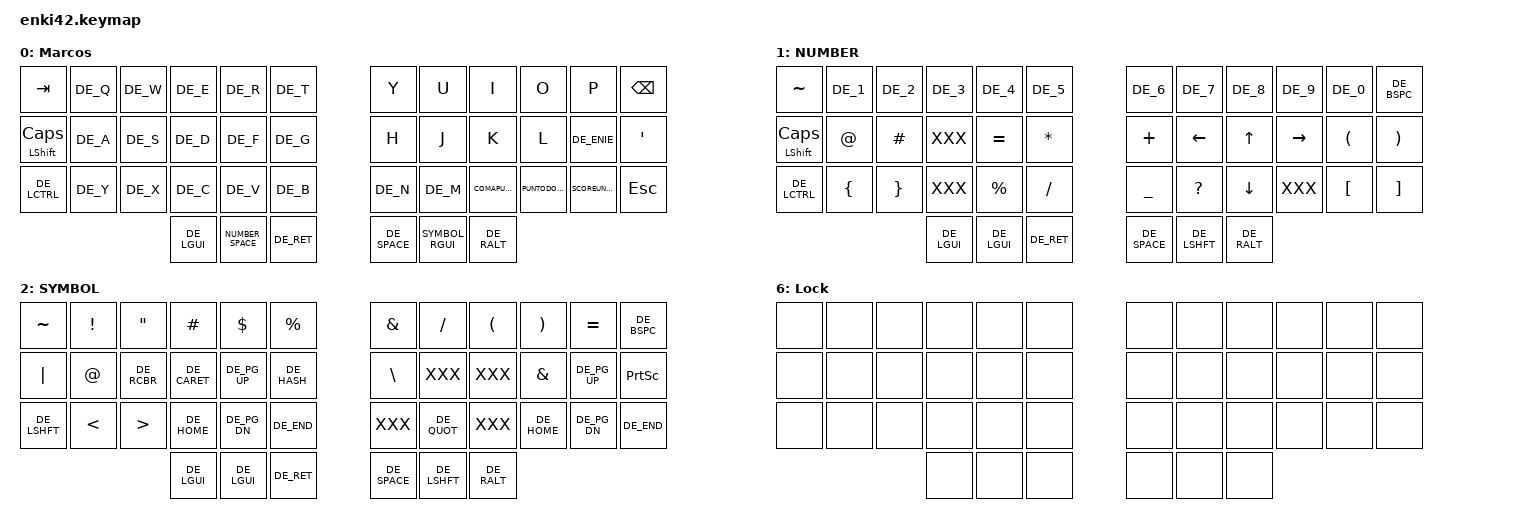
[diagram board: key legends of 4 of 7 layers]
/* ========================================
FileName: corne.keymap
Date: 15:17 23.September.2022
Author: Marcos Chow Castro
Email: mctechnology170318@gmail.com
GitHub: https://github.com/mctechnology17
Brief: keymap for the wireless corne keyboard
                             ╔═╦═╦═╗
                      ╔════╗ ║║║║║╔╝
                      ║╔╗╔╗║ ║║║║║╚╗
                      ╚╝║║╚╝ ║╠═╩╩═╝
                        ║╠═╦═╣╚╦═╦╦═╦╗╔═╦═╦╦╗
                        ║║╩╣═╣║║║║║╬║╚╣╬║╬║║║
                        ╚╩═╩═╩╩╩╩═╩═╩═╩═╬╗╠╗║
                                        ╚═╩═╝
Copyright (c) 2020 The ZMK Contributors
SPDX-License-Identifier: MIT
========================================= */
// ### include {{{
#include <behaviors.dtsi>
#include <dt-bindings/zmk/keys.h>
#include <dt-bindings/zmk/bt.h>
#include <dt-bindings/zmk/outputs.h>
#include <dt-bindings/zmk/ext_power.h>
#include <dt-bindings/led/led.h>
#include <dt-bindings/zmk/backlight.h>
#include <dt-bindings/zmk/rgb.h>
#include <dt-bindings/zmk/reset.h>
#include "keymap_german_mac_iso_zmk.h"
#include "keypos_42keys.h"
#include "config_zmk.h"
//#include "mouse.dtsi"
//&led_strip {
//    chain-length = <27>;
//};
// }}}
/ {
// ### macros {{{
   macros {
      #include "macros.dtsi"
   };
// }}}
// ### combos {{{
   combos {
      compatible = "zmk,combos";

      unlock {
         bindings = <&to DEFAULT>;
         key-positions = <LT5 LH0 RH0 RT5>;
         layers = <LOCK>;
      };

      lock {
         bindings = <&to LOCK>;
         key-positions = <LT5 RH0>;
         layers = <LX_>;
      };
   };
// }}}
   // ### conditional_layers {{{
   conditional_layers {
        compatible = "zmk,conditional-layers";

        tri_layer {
            if-layers = <SYMBOL FUNCTION>;
            then-layer = <LX_>;
        };
    };

   //}}}

 // ### MOD MORPH {{{

 behaviors {
        COMAPUNTOCOMA: coma_puntocoma {
            compatible = "zmk,behavior-mod-morph";
            #binding-cells = <0>;
            bindings = <&kp COMMA>, <&kp SEMICOLON>;
            mods = <(MOD_LSFT)>;
        };
    };
 behaviors {
        PUNTODOSPUNTOS: punto_dospuntos {
            compatible = "zmk,behavior-mod-morph";
            #binding-cells = <0>;
            bindings = <&kp DOT>, <&kp COLON>;
            mods = <(MOD_LSFT)>;
        };
    };

 behaviors {
        SCOREUNDERSCORE: guion_guionbajo {
            compatible = "zmk,behavior-mod-morph";
            #binding-cells = <0>;
            bindings = <&kp MINUS>, <&kp UNDER>;
            mods = <(MOD_LSFT)>;
        };
    };


  //}}}
   keymap {
      compatible = "zmk,keymap";
      // ### default_layer {{{
      default_layer {
      /*.------------------------------------------------.                         .-------------------------------------------------.
         |TAB     |   Q   |   W   |   E   |   R   |   T   |                         |   Y   |   U   |   I   |   O   |   P   | BACKSPC |
         |--------+-------+-------+-------+-------+-------|                         |-------+-------+-------+-------+-------+---------|
         |SHIFT   |   A   |   S   |   D   |   F   |   G   |                         |   H   |   J   |   K   |   L   |  ñ    |   '     |
         |--------+-------+-------+-------+-------+-------|                         |-------+-------+-------+-------+-------+---------|
         |CTRL    |   Y   |   X   |   C   |   V   |   B   |                         |   N   |   M   |   ,   |  .    |  _    |   ESC   |
         '---------------------------------------------------------|       |----------------------------------------------------------'
                                  |  WIN    |  LT1       |   ENTER |       | SPACE | LT2 CMD   |  RALT |
                                  '--------------------------------'       '----------------------------------'*/
         display-name = "Marcos";
         bindings = <
         &kp TAB          DE_Q  DE_W  DE_E  DE_R  DE_T                      &kp Y   &kp U  &kp I           &kp O           &kp P      &kp BSPC
         &mt LSHIFT CLCK   DE_A   DE_S   DE_D   DE_F   DE_G                        &kp H   &kp J  &kp K           &kp L           DE_ENIE    &kp APOS   
         DE_LCTRL         DE_Y  DE_X  DE_C  DE_V  DE_B                      DE_N    DE_M   &COMAPUNTOCOMA  &PUNTODOSPUNTOS &SCOREUNDERSCORE  &kp ESC
                                  DE_LGUI  NUMBER_SPACE DE_RET           DE_SPACE SYMBOL_RGUI DE_RALT
            >;
      };
      // }}}
      // ### number_layer {{{
      number_layer {
       /*.-------------------------------------------------.                         .-------------------------------------------------.
         |    ~    |   1   |   2   |   3   |   4   |   5   |                         |   6   |   7   |   8   |   9   |   0   |BACKSPC  |
         |---------+-------+-------+-------+-------+-------|                         |-------+-------+-------+-------+-------+---------|
         | SHIFT   |   @   |   #   |       |   =   |   *   |                         |   +   |  LEFT |   UP  |  RIGHT|  (     |   )    |
         |---------+-------+-------+-------+-------+-------|                         |-------+-------+-------+-------+-------+---------|
         | CTRL   |    {  |   }    |       |   %   |   /   |                        |   -   |   ?   |  DOWN |       |  [     |   ]    |
         '----------------------------------------------------------|       |----------------------------------------------------------'
                                   |  WIN |  CMD  |     ENTER       |       |    SPACE    |  LSFT |      ALTGR    |
                                   '--------------------------------'       '--------------------------------'*/
         display-name = "NUMBER";
         bindings = <
         &kp TILDE       DE_1     DE_2       DE_3        DE_4        DE_5                        DE_6       DE_7          DE_8      DE_9        DE_0        DE_BSPC
         &mt LSHIFT CLCK &kp AT   &kp HASH   XXX           &kp EQUAL   &kp ASTRK                 &kp PLUS   &kp LEFT      &kp UP    &kp RIGHT   &kp LPAR    &kp RPAR
         DE_LCTRL        &kp LBRC &kp RBRC   XXX            &kp PERCENT &kp SLASH                &kp UNDER  &kp QUESTION  &kp DOWN    XXX       &kp LBKT    &kp RBKT
                                          DE_LGUI   DE_LGUI    DE_RET                               DE_SPACE DE_LSHFT DE_RALT
            >;
      };
      // }}}
      // ### symbol_layer {{{
      symbol_layer {
       /*.------------------------------------------------.          TODO:          .-------------------------------------------------.
         |    ~   |   !   |   "   |   #   |   $   |    %   |                         |  &    |   /   |   (   |   )   |   =   |BACKSPC  |
         |--------+-------+-------+-------+-------+-------|                         |-------+-------+-------+-------+-------+---------|
         |    |  |   @   |   }   |   ^   |       |   #    |                         |   \   |       |       |  &    |PAGE_UP|PRINTSCR |
         |--------+-------+-------+-------+-------+-------|                         |-------+-------+-------+-------+-------+---------|
         |SHIFT   |    <  |   >   |  HOME |PAGE_DO|  END  |                         |      |   '   |       |  HOME |PAGE_DO|   END   |
         '---------------------------------------------------------|       |----------------------------------------------------------'
                                  |  WIN    |  CMD        | ENTER  |       |  SPACE | LSFT |       ALTGR      |
                                  '--------------------------------'       '--------------------------------'*/
         display-name = "SYMBOL";
         bindings = <
         &kp TILDE &kp EXCL       &kp DQT          &kp HASH &kp DLLR   &kp PRCNT                  &kp AMPS       &kp SLASH   &kp LPAR  &kp RPAR &kp EQUAL DE_BSPC
         &kp PIPE  &kp AT         DE_RCBR          DE_CARET DE_PG_UP   DE_HASH                    &kp BACKSLASH    XXX        XXX      &kp AMPS DE_PG_UP  &kp PRINTSCREEN
         DE_LSHFT  &kp LESS_THAN  &kp GREATER_THAN DE_HOME  DE_PG_DN   DE_END                        XXX          DE_QUOT      XXX      DE_HOME  DE_PG_DN  DE_END
                                                    DE_LGUI   DE_LGUI    DE_RET                    DE_SPACE DE_LSHFT DE_RALT
         >;
      };
      // }}}
      // ### function_layer {{{
      function_layer {
       /*.------------------------------------------------.                         .-------------------------------------------------.
         |    F1  |  F2   |   F3  |   F4  | SPELL |TRADUCT|                         |DE_F13 | DE_F14|DE_F15 | DE_F16| BRI_DN| BRI_UP  |
         |--------+-------+-------+-------+-------+-------|                         |-------+-------+-------+-------+-------+---------|
         |    F5  |  F6   |   F7  |    F8 |   \   |ALFRED |                         |C-A-DEL|DE_F19 |DE_F20 |CLR_LIN|PAGE_UP|         |
         |--------+-------+-------+-------+-------+-------|                         |-------+-------+-------+-------+-------+---------|
         |    F9  |   F10 |   F11 |   F12 |ALFRED |EMOJI  |                         |L_SHIFT|L_SHIFT|R_SHIFT|  HOME |PAGE_DO|    END  |
         '----------------------------------------------------------|       |----------------------------------------------------------'
                                   |  CTRL    |  CMD       |   ALT  |       |  TAB   |   ´   |          CTRL |
                                   '--------------------------------'       '--------------------------------'
         LCTL(LGUI(KC_D)), LCTL(LGUI(KC_SPC))*/
         display-name = "FUNCTION";
         bindings = <
         DE_F1  DE_F2   DE_F3   DE_F4    SPELL    TRADUCT                   &macro6   &macro5   &macro8    &macro2   DE_BRI_DN  DE_BRI_UP
         DE_F5  DE_F6   DE_F7   DE_F8    DE_BSLS  SNIPPET                   TASKM     &macro1   &macro3    &macro4   DE_PG_UP   &macro9
         DE_F9  DE_F10  DE_F11  DE_F12   CLIPBRD  EMOJI                     DE_LSHFT  DE_LSHFT  DE_RSHFT   DE_HOME   DE_PG_DN   DE_END
                                         DE_LCTRL DE_LGUI  DE_LALT  DE_TAB  DE_ACUT   DE_LCTRL
                              >;
                      };
      // }}}
      // ### media_layer {{{
      media_layer {
       /*.------------------------------------------------.                         .-------------------------------------------------.
         |        |SC_FLOW|TXTSNIP|SC_SHOT|OP_TERM|       |                         |POS1   |POS2   |LANG_1 |LANG_2 | STOP  |  DELETE |
         |--------+-------+-------+-------+-------+-------|                         |-------+-------+-------+-------+-------+---------|
         |bootlder|SC_SPSF|SC_RE  |       |       |       |                         |POS3   |POS4   |LANG_3 |SHUFFLE|VOL_UP |PLAY/PAUS|
         |--------+-------+-------+-------+-------+-------|                         |-------+-------+-------+-------+-------+---------|
         |reset   |       |       |       |       |       |                         |       |       |  MUTE |  PREV |VOL_DOW|  NEXT   |
         '---------------------------------------------------------|       |----------------------------------------------------------'
                                  |  CTRL    |  CMD       |   ALT  |       |  SPACE | ALTGR |          CTRL |
                                  '--------------------------------'       '--------------------------------'*/
         display-name = "MEDIA";
         bindings = <
         XXX          SC_FLOW  TXTSNIP  SC_SHOT OP_TERM   XXX               POS1        POS2      DE_LANG1   DE_LANG2    DE_STOP    DE_DEL
         &bootloader  SC_SPSF  SC_RE    XXX     XXX       XXX               POS3        POS4      DE_LANG3   DE_SHUFFLE  DE_VOL_UP  DE_PLAY
         &sys_reset   XXX      XXX      XXX     XXX       XXX                           &ene_big  DE_MUTE    DE_PREV     DE_VOL_DN  DE_NEXT
                                        DE_LCTRL  DE_LGUI  DE_LALT  DE_SPACE  DE_RALT DE_LCTRL
                              >;
                      };
      // }}}
      // ### mouse_layer: mouse {{{
     // mouse_layer {
       /*.------------------------------------------------.                         .-------------------------------------------------.
         |WH_LEFT |WH_RIGH|       |OUT_USB|OUT_BLE|OUT_TOG|                         | BRD-  | BRI+  |  SPD- | SPI+  |WH_DOWN| WH_UP   |
         |--------+-------+-------+-------+-------+-------|                         |-------+-------+-------+-------+-------+---------|
         |        |CLICK_1|CLICK_2|CLICK_3|BT_PRV | BT_NXT|                         | HUD-  | HUI+  |       |CLICK_1| UP    |CLICK_2  |
         |--------+-------+-------+-------+-------+-------|                         |-------+-------+-------+-------+-------+---------|
         |BT_CLR  |BT_0   |BT_1   |BT_2   |BT_3   |BT_4   |                         | SAD-  | SAI+  | RESET | LEFT  | DOWN  | RIGHT   |
         '---------------------------------------------------------|       |----------------------------------------------------------'
                                  |EP_OFF  | EP_ON|         EP_TOG |       | EFF-  | EFR+   |   RGB_TOG     |
                                  '--------------------------------'       '--------------------------------'*/
       //  display-name = "MOUSE";
       //  bindings = <
       //  SCROLL_LEFT SCROLL_RIGHT XXX         &out OUT_USB &out OUT_BLE  &out OUT_TOG             &rgb_ug RGB_BRD &rgb_ug RGB_BRI &rgb_ug RGB_SPD                    &rgb_ug RGB_SPI SCROLL_DOWN SCROLL_UP
       //  XXX         CLICK_LEFT   CLICK_RIGHT CLICK_MIDDLE &bt BT_PRV    &bt BT_NXT               &rgb_ug RGB_HUD &rgb_ug RGB_HUI &rgb_ug RGB_COLOR_HSB(0,0,100)     CLICK_LEFT      MOVE_UP     CLICK_RIGHT
       //  &bt BT_CLR  &bt BT(0)    &bt BT(1)   &bt BT(2)    &bt BT(3)     &bt BT(4)                &rgb_ug RGB_SAD &rgb_ug RGB_SAI &rgb_ug RGB_COLOR_HSB(224,100,100) MOVE_LEFT       MOVE_DOWN   MOVE_RIGHT
       //                          &ext_power EP_OFF    &ext_power EP_ON   &ext_power EP_TOG    &rgb_ug RGB_EFF &rgb_ug RGB_EFR &rgb_ug RGB_TOG
        //                      >;
         //             };
      // }}}
      // ### linux_symbol {{{
      linux_symbol {
       /*.------------------------------------------------.          TODO:          .-------------------------------------------------.
         |   $    |   (   |   )   |   [   |   ]   |   &   |                         |  `    |   '   |   ´   |bootldr| reset |BACKSPC  |
         |--------+-------+-------+-------+-------+-------|                         |-------+-------+-------+-------+-------+---------|
         |   %    |   {   |   }   |   ^   |PAGE_UP|   #   |                         |    \  |   |   |   /   |   &   |  UP   |   ENTER |
         |--------+-------+-------+-------+-------+-------|                         |-------+-------+-------+-------+-------+---------|
         |SHIFT   |    <  |   >   |  HOME |PAGE_DO|  END  |                         |   ~   |   '   |   @   |  LEFT |  DOWN |   RIGHT |
         '---------------------------------------------------------|       |----------------------------------------------------------'
         DE_LN_DQUO               |DE_F13 |    DE_F14     | DE_F15 |       |  SPACE | ALTGR |          CTRL |
                                  '--------------------------------'       '--------------------------------'*/
         display-name = "LX_";
         bindings = <
         DE_DLR   DE_LN_LPRN  DE_LN_RPRN   DE_LN_LBRC  DE_LN_RBRC  DE_LN_AMPS                DE_GRV      DE_QUOT     DE_ACUT     &bootloader &sys_reset  DE_BSPC
         DE_PERC  DE_LN_LCBR  DE_LN_RCBR   DE_LN_CARET DE_PG_UP    DE_HASH                   DE_LN_BSLH  DE_LN_PIPE  DE_LN_FSLH  DE_LN_AMPS  DE_UP       DE_RET
         DE_LSHFT DE_LN_LABK  DE_LN_RABK   DE_HOME     DE_PG_DN    DE_END                    DE_LN_TILDE DE_QUOT     DE_LN_AT    NAV_LEFT    DE_DOWN     NAV_RIGHT
                                              &macro7   &macro5  &macro8  DE_SPACE  DE_RALT  DE_LCTRL
         >;
      };
      // }}}
   // ### lock  {{{
      lock {
         display-name = "Lock";
         bindings = <
            &none  &none  &none  &none  &none  &none  &none  &none  &none  &none  &none  &none
            &none  &none  &none  &none  &none  &none  &none  &none  &none  &none  &none  &none
            &none  &none  &none  &none  &none  &none  &none  &none  &none  &none  &none  &none
                                 &none  &none  &none  &none  &none  &none
            >;
        };
   //}}}
   };
};

// vim: filetype=dts fdm=marker:
